# R7FA6E2BB register map
Vendor: Renesas Electronics Corporation; Series: RA6; File version: 1.30.00
CPU: CM33 r0p4, little endian, MPU, FPU, VTOR, 4 interrupt priority bits, 96 interrupts
Registers are 32-bit, read-write, reset 0x0 unless marked. A register's access mark holds for its fields unless they carry their own. Offsets are from the block's base; [hi:lo] are bit positions; {n}, {i} and the like mark numbered series.

## ECCMB
Base 0x4012F200
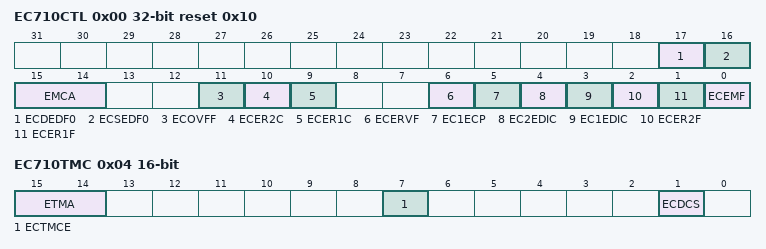
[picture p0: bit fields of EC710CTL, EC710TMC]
0x00 EC710CTL reset 0x10 — ECC Control Register
  [17] ECDEDF0 ro — ECC Dual Bit Error Address Detection Flag
  [16] ECSEDF0 ro — ECC Single bit Error Address Detection Flag
  [15:14] EMCA — Access Control to ECC Mode Select bit
  [11] ECOVFF ro — ECC Overflow Detection Flag
  [10] ECER2C — 2-bit ECC Error Detection Flag Clear
  [9] ECER1C — Accumulating ECC Error Detection and Correction Flag Clear
  [6] ECERVF — ECC Error Judgment Enable Flag
  [5] EC1ECP — ECC 1-bit Error Correction Permission
  [4] EC2EDIC — ECC 2-bit Error Detection Interrupt Control
  [3] EC1EDIC — ECC 1-bit Error Detection Interrupt Control
  [2] ECER2F ro — 2-bit ECC Error Detection Flag
  [1] ECER1F ro — ECC Error Detection and Correction Flag
  [0] ECEMF ro — ECC Error Message Flag
0x04 EC710TMC 16-bit — ECC Test Mode Control Register
  [15:14] ETMA — ECC Test Mode Bit Access Control
  [7] ECTMCE — ECC Test Mode Control Enable
  [1] ECDCS — ECC Decode Input Select
0x0C EC710TED — ECC Test Substitute Data Register
  [31:0] ECEDB — ECC Test Substitute Data
0x10 EC710EAD0 ro — ECC Error Address Register
  [10:0] ECEAD — ECC Error Address

## GPT_OPS — Output Phase Switching Controller
Base 0x40169A00
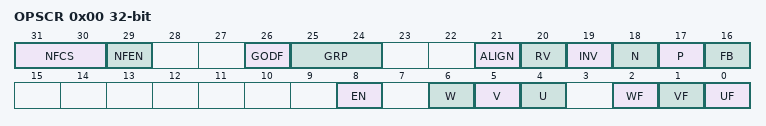
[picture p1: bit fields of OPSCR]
0x00 OPSCR — Output Phase Switching Control Register
  [31:30] NFCS — External Input Noise Filter Clock Selection
  [29] NFEN — External Input Noise Filter Enable
  [26] GODF — Group Output Disable Function
  [25:24] GRP — Output Disabled Source Selection
  [21] ALIGN — Input Phase Alignment
  [20] RV — Output Phase Rotation Direction Reversal Control
  [19] INV — Output Phase Invert Control
  [18] N — Negative,Phase Output (N) Control
  [17] P — Positive,Phase Output (P) Control
  [16] FB — External Feedback Signal Enable
  [8] EN — Output Phase Enable
  [6] W ro — Input W,Phase Monitor
  [5] V ro — Input V,Phase Monitor
  [4] U ro — Input U,Phase Monitor
  [2] WF
  [1] VF
  [0] UF

## DAC12 — 12-bit D/A converter
Base 0x40171000
{0x0+2i} DADR{i} (i=0..1) 16-bit — D/A Data Register {i}
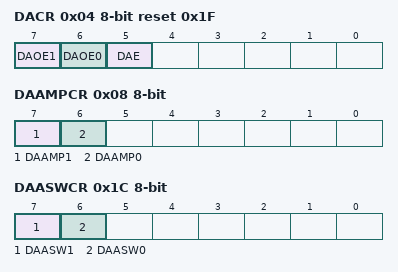
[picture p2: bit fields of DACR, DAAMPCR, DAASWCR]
0x04 DACR 8-bit reset 0x1F — D/A Control Register
  [7] DAOE1 — D/A Output Enable 1
  [6] DAOE0 — D/A Output Enable 0
  [5] DAE — D/A Enable
0x05 DADPR 8-bit — DADRn Format Select Register
  [7] DPSEL — DADRn Format Select
0x06 DAADSCR 8-bit — D/A A/D Synchronous Start Control Register
  [7] DAADST — D/A A/D Synchronous Conversion
0x08 DAAMPCR 8-bit — D/A Output Amplifier Control Register
  [7] DAAMP1 — Amplifier Control 1
  [6] DAAMP0 — Amplifier Control 0
0x1C DAASWCR 8-bit — D/A Amplifier Stabilization Wait Control Register
  [7] DAASW1 — D/A Amplifier Stabilization Wait 1
  [6] DAASW0 — D/A Amplifier Stabilization Wait 0
0x10C0 DAADUSR 8-bit — D/A A/D Synchronous Unit Select Register
  [0] AMADSEL0 — A/D Unit 0 Select

## TSD — Temperature Sensor Calibration Data
Base 0x407FB000
0x17C TSCDR ro (reset mask 0xFFFF0000) — Temperature Sensor Calibration Data Register
  [15:0] TSCDR — Temperature Sensor Calibration Data

## FLAD — Data Flash
Base 0x407FC000
0x40 FCKMHZ 8-bit reset 0x3C — Data Flash Access Frequency Register

## FACI — Flash/CPU Interface
Base 0x407FE000
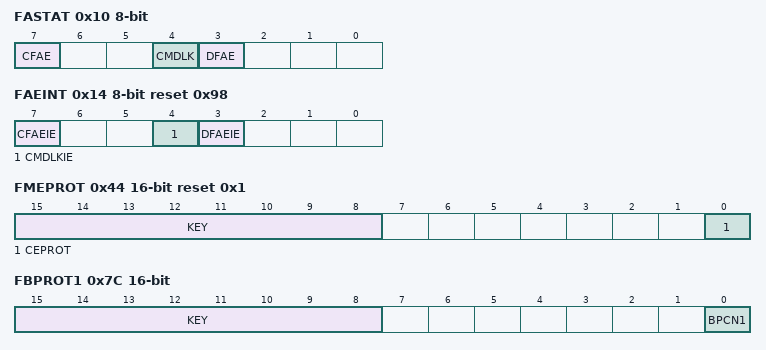
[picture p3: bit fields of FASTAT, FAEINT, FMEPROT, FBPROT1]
0x10 FASTAT 8-bit — Flash Access Status Register
  [7] CFAE — Code Flash Memory Access Violation Flag
  [4] CMDLK ro — Command Lock Flag
  [3] DFAE — Data Flash Memory Access Violation Flag
0x14 FAEINT 8-bit reset 0x98 — Flash Access Error Interrupt Enable Register
  [7] CFAEIE — Code Flash Memory Access Violation Interrupt Enable
  [4] CMDLKIE — Command Lock Interrupt Enable
  [3] DFAEIE — Data Flash Memory Access Violation Interrupt Enable
0x18 FRDYIE 8-bit — Flash Ready Interrupt Enable Register
  [0] FRDYIE — Flash Ready Interrupt Enable
0x30 FSADDR — FACI Command Start Address Register
0x34 FEADDR — FACI Command End Address Register
  [31:0] FEADDR — End Address for FACI Command Processing
0x44 FMEPROT 16-bit reset 0x1 — Flash P/E Mode Entry Protection Register
  [15:8] KEY wo — Key Code
  [0] CEPROT — Code Flash P/E Mode Entry Protection
0x7C FBPROT1 16-bit — Flash Block Protection for Secure Register
  [15:8] KEY wo — Key Code
  [0] BPCN1 — Block Protection for Secure Cancel
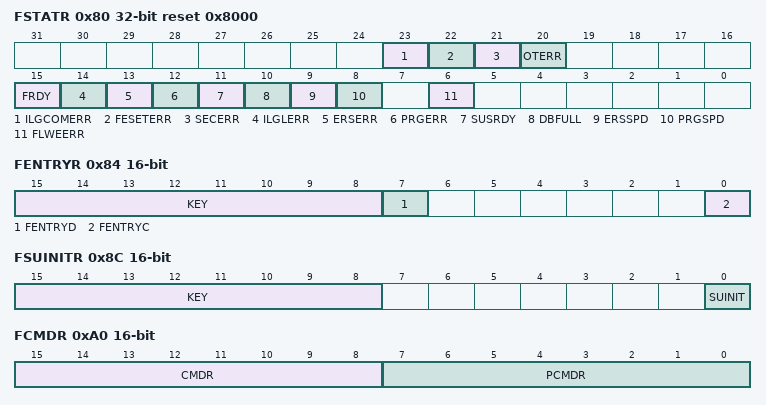
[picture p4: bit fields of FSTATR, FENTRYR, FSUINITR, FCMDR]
0x80 FSTATR reset 0x8000 — Flash Status Register
  [23] ILGCOMERR ro — Illegal Command Error
  [22] FESETERR ro — FENTRY Setting Error
  [21] SECERR ro — Security Error
  [20] OTERR ro — Other Error
  [15] FRDY ro — Flash Ready Flag
  [14] ILGLERR ro — Illegal Command Error Flag
  [13] ERSERR ro — Erasure Error Flag
  [12] PRGERR ro — Programming Error Flag
  [11] SUSRDY ro — Suspend Ready Flag
  [10] DBFULL ro — Data Buffer Full Flag
  [9] ERSSPD ro — Erasure Suspend Status Flag
  [8] PRGSPD ro — Programming Suspend Status Flag
  [6] FLWEERR ro — Flash Write/Erase Protect Error Flag
0x84 FENTRYR 16-bit — Flash P/E Mode Entry Register
  [15:8] KEY wo — Key Code
  [7] FENTRYD — Data Flash P/E Mode Entry
  [0] FENTRYC — Code Flash P/E Mode Entry
0x8C FSUINITR 16-bit — Flash Sequencer Setup Initialization Register
  [15:8] KEY wo — Key Code
  [0] SUINIT — Set,Up Initialization
0xA0 FCMDR 16-bit ro — FACI Command Register
  [15:8] CMDR — Command Flag
  [7:0] PCMDR — Pre,command Flag
0xD0 FBCCNT 8-bit — Blank Check Control Register
  [0] BCDIR — Blank Check Direction
0xD4 FBCSTAT 8-bit — Blank Check Status Register
  [0] BCST ro — Blank Check Status Flag
0xD8 FPSADDR — Data Flash Programming Start Address Register
  [16:0] PSADR ro — Programmed Area Start Address
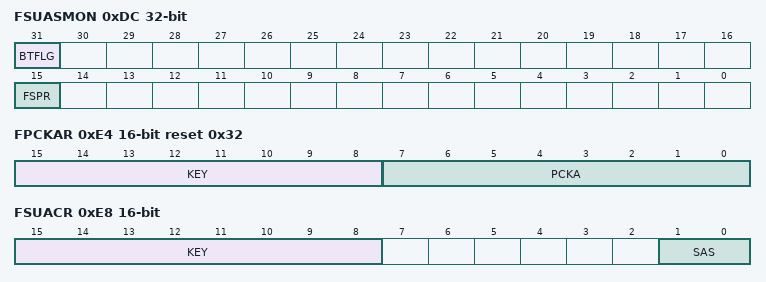
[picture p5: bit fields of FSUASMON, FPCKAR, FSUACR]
0xDC FSUASMON ro (reset mask 0x7FFF7FFF) — Flash Startup Area Select Monitor Register
  [31] BTFLG — Flag of Startup Area Select for Boot Swap
  [15] FSPR — Protection Programming Flag to set Boot Flag and Startup Area Control
0xE0 FCPSR 16-bit — Flash Sequencer Processing Switching Register
  [0] ESUSPMD — Erasure Suspend Mode
0xE4 FPCKAR 16-bit reset 0x32 — Flash Sequencer Processing Clock Notification Register
  [15:8] KEY wo — Key Code
  [7:0] PCKA — Flash Sequencer Operating Clock Notification
0xE8 FSUACR 16-bit — Flash Startup Area Control Register
  [15:8] KEY wo — Key Code
  [1:0] SAS — Startup Area Select

## QSPI — Quad Serial Peripheral Interface
Base 0x64000000
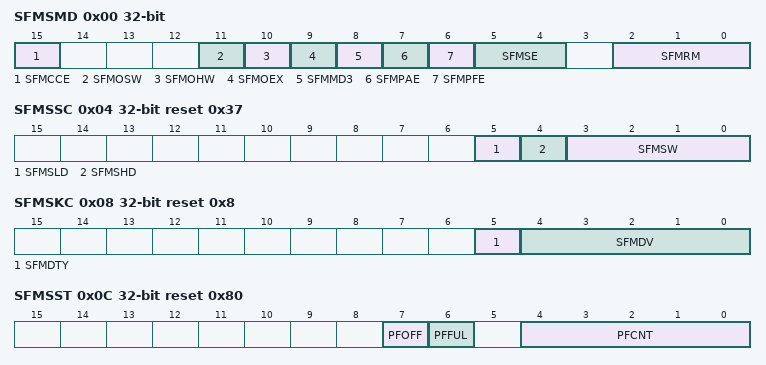
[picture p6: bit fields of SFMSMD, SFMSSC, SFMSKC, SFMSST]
0x00 SFMSMD — Transfer Mode Control Register
  [15] SFMCCE — Read instruction code select
  [11] SFMOSW — Setup time adjustment for serial transmission
  [10] SFMOHW — Hold time adjustment for serial transmission
  [9] SFMOEX — Extension select for the I/O buffer output enable signal for the serial interface
  [8] SFMMD3 — SPI mode select.
  [7] SFMPAE — Function select for stopping prefetch at locations other than on byte boundaries
  [6] SFMPFE — Prefetch function select
  [5:4] SFMSE — QSSL extension function select after SPI bus access
  [2:0] SFMRM — Serial interface read mode select
0x04 SFMSSC reset 0x37 — Chip Selection Control Register
  [5] SFMSLD — QSSL Signal Setup Time
  [4] SFMSHD — QSSL Signal Hold Time
  [3:0] SFMSW — Minimum High,level Width Select for QSSL Signal
0x08 SFMSKC reset 0x8 — Clock Control Register
  [5] SFMDTY — Duty ratio correction function select for the QSPCLK signal when divided by an odd number
  [4:0] SFMDV — Serial interface reference cycle select. (Pay attention to irregularities.)
0x0C SFMSST ro reset 0x80 — Status Register
  [7] PFOFF — Prefetch function operating state
  [6] PFFUL — Prefetch buffer state
  [4:0] PFCNT — Number of bytes of prefetched data
0x10 SFMCOM (reset mask 0xFFFFFF00) — Communication Port Register
  [7:0] SFMD — Port for direct communication with the SPI bus
0x14 SFMCMD — Communication Mode Control Register
  [0] DCOM — Mode select for communication with the SPI bus
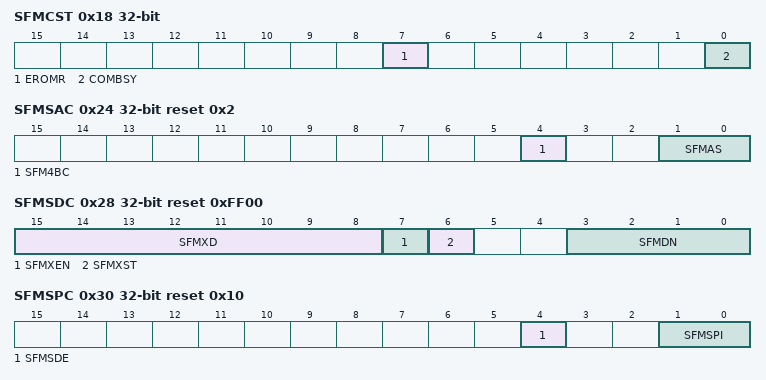
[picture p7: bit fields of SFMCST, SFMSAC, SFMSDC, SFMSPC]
0x18 SFMCST — Communication Status Register
  [7] EROMR — ROM access detection status in direct communication mode
  [0] COMBSY ro — SPI bus cycle completion state in direct communication
0x20 SFMSIC — Instruction Code Register
  [7:0] SFMCIC — Serial flash instruction code to substitute
0x24 SFMSAC reset 0x2 — Address Mode Control Register
  [4] SFM4BC — Selection of instruction code automatically generated when the serial interface address width is 4 bytes
  [1:0] SFMAS — Number of address bytes select for the serial interface
0x28 SFMSDC reset 0xFF00 — Dummy Cycle Control Register
  [15:8] SFMXD — Mode data for serial flash (Controls XIP mode.)
  [7] SFMXEN — XIP mode permission
  [6] SFMXST ro — XIP mode status
  [3:0] SFMDN — Number of dummy cycles select for Fast Read instructions
0x30 SFMSPC reset 0x10 — SPI Protocol Control Register
  [4] SFMSDE — QSPCLK extended selection bit when switching I/O of QIOn pin
  [1:0] SFMSPI — SPI protocol select
0x34 SFMPMD — Port Control Register
  [2] SFMWPL — WP pin level specification
0x804 SFMCNT1 — External QSPI Address Register
  [31:26] QSPI_EXT — Bank switching address
